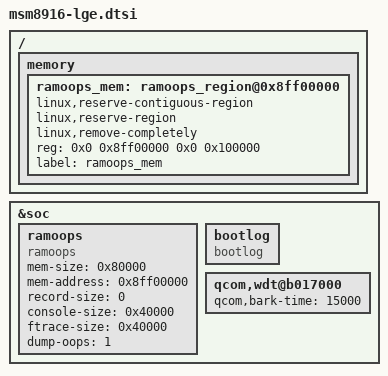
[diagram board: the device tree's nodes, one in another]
/* Copyright (c) 2012, Code Aurora Forum. All rights reserved.
 *
 * This program is free software; you can redistribute it and/or modify
 * it under the terms of the GNU General Public License version 2 and
 * only version 2 as published by the Free Software Foundation.
 *
 * This program is distributed in the hope that it will be useful,
 * but WITHOUT ANY WARRANTY; without even the implied warranty of
 * MERCHANTABILITY or FITNESS FOR A PARTICULAR PURPOSE.  See the
 * GNU General Public License for more details.
 */

#include "../../qcom/msm8916.dtsi"
#include "msm8916-lge-common.dtsi"

/ {
	memory {
		ramoops_mem: ramoops_region@0x8ff00000 {
			linux,reserve-contiguous-region;
			linux,reserve-region;
			linux,remove-completely;
			reg = <0x0 0x8ff00000 0x0 0x100000>;
			label = "ramoops_mem";
		};
	};
};

&soc {
	ramoops {
		compatible = "ramoops";
		mem-size = <0x80000>;
		mem-address = <0x8ff00000>;
		record-size = <0>;
		console-size = <0x40000>;
		ftrace-size = <0x40000>;
		dump-oops = <1>;
	};

	bootlog {
		compatible = "bootlog";
		/*
		 * Actually, physical address & size are read from "/chosen" node.
		 * The properties are "lge,log_buffer_phy_addr" and "lge,log_buffer_size" added in LK.
		 * LOGBUF_SIZE is defined in android/bootable/bootloader/lk/include/debug.h.
		 * LOGBUF_PHYS_ADDR is defined in android/bootable/bootloader/lk/target/msm8916_betae/rules.mk.
		 */
	};

        qcom,wdt@b017000 {
                qcom,bark-time = <15000>;
        };
};
